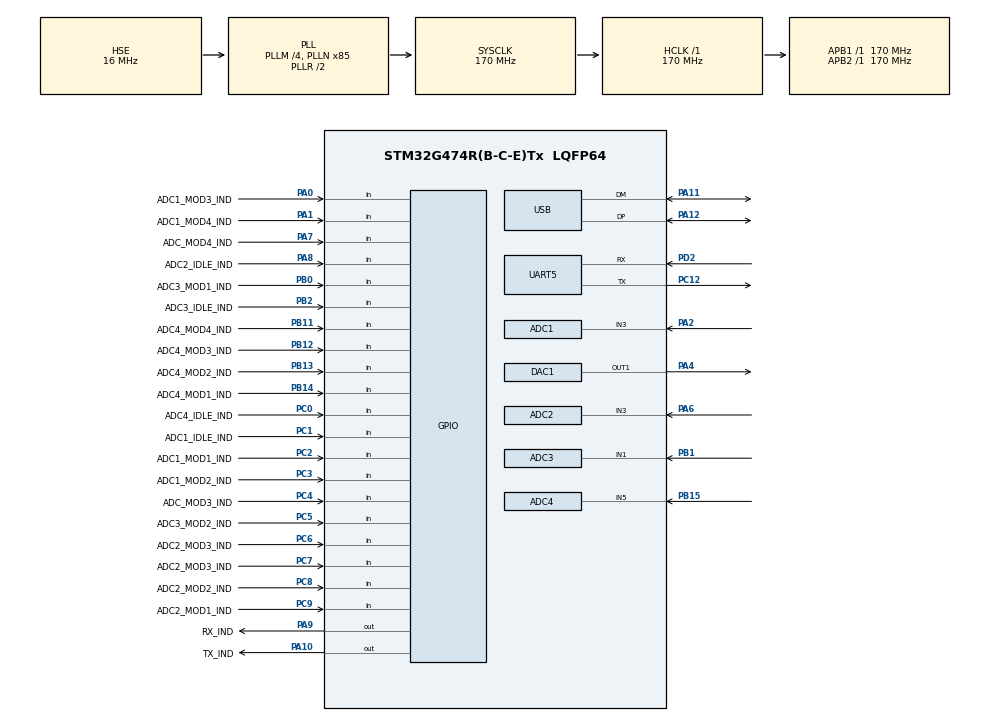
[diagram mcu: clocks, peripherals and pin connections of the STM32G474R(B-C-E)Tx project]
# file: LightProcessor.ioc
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ADC1.Channel-1\#ChannelRegularConversion=ADC_CHANNEL_3
ADC1.NbrOfConversionFlag=1
ADC1.OffsetNumber-1\#ChannelRegularConversion=ADC_OFFSET_NONE
ADC1.Rank-1\#ChannelRegularConversion=1
ADC1.SamplingTime-1\#ChannelRegularConversion=ADC_SAMPLETIME_2CYCLES_5
ADC1.ScanConvMode-ADC_Settings=ADC_SCAN_DISABLE
ADC1.master=1
ADC2.Channel-0\#ChannelRegularConversion=ADC_CHANNEL_3
ADC2.NbrOfConversionFlag=1
ADC2.OffsetNumber-0\#ChannelRegularConversion=ADC_OFFSET_NONE
ADC2.Rank-0\#ChannelRegularConversion=1
ADC2.SamplingTime-0\#ChannelRegularConversion=ADC_SAMPLETIME_2CYCLES_5
ADC3.Channel-0\#ChannelRegularConversion=ADC_CHANNEL_1
ADC3.NbrOfConversionFlag=1
ADC3.OffsetNumber-0\#ChannelRegularConversion=ADC_OFFSET_NONE
ADC3.Rank-0\#ChannelRegularConversion=1
ADC3.SamplingTime-0\#ChannelRegularConversion=ADC_SAMPLETIME_2CYCLES_5
ADC3.master=1
ADC4.Channel-0\#ChannelRegularConversion=ADC_CHANNEL_5
ADC4.NbrOfConversionFlag=1
ADC4.OffsetNumber-0\#ChannelRegularConversion=ADC_OFFSET_NONE
ADC4.Rank-0\#ChannelRegularConversion=1
ADC4.SamplingTime-0\#ChannelRegularConversion=ADC_SAMPLETIME_2CYCLES_5
Mcu.Family=STM32G4
Mcu.Name=STM32G474R(B-C-E)Tx
Mcu.Package=LQFP64
NVIC.ADC1_2_IRQn=true\:0\:0\:false\:false\:true\:true\:true\:true
NVIC.ADC3_IRQn=true\:0\:0\:false\:false\:true\:true\:true\:true
NVIC.ADC4_IRQn=true\:0\:0\:false\:false\:true\:true\:true\:true
NVIC.PriorityGroup=NVIC_PRIORITYGROUP_4
NVIC.TIM2_IRQn=true\:0\:0\:false\:false\:true\:true\:true\:true
NVIC.UART5_IRQn=true\:0\:0\:false\:false\:true\:true\:true\:true
PA0.GPIO_Label=ADC1_MOD3_IND
PA0.GPIO_PuPd=GPIO_PULLDOWN
PA0.Signal=GPIO_Input
PA1.GPIO_Label=ADC1_MOD4_IND
PA1.GPIO_PuPd=GPIO_PULLDOWN
PA1.Signal=GPIO_Input
PA10.GPIO_Label=TX_IND
PA10.GPIO_PuPd=GPIO_PULLDOWN
PA10.Signal=GPIO_Output
PA11.Mode=Device
PA11.Signal=USB_DM
PA12.Mode=Device
PA12.Signal=USB_DP
PA13.Mode=Serial_Wire
PA13.Signal=SYS_JTMS-SWDIO
PA14.Mode=Serial_Wire
PA14.Signal=SYS_JTCK-SWCLK
PA2.Mode=IN3-Single-Ended
PA2.Signal=ADC1_IN3
PA4.Signal=COMP_DAC11_group
PA6.Mode=IN3-Single-Ended
PA6.Signal=ADC2_IN3
PA7.GPIO_Label=ADC_MOD4_IND
PA7.GPIO_PuPd=GPIO_PULLDOWN
PA7.Signal=GPIO_Input
PA8.GPIO_Label=ADC2_IDLE_IND
PA8.GPIO_PuPd=GPIO_PULLDOWN
PA8.Signal=GPIO_Input
PA9.GPIO_Label=RX_IND
PA9.GPIO_PuPd=GPIO_PULLDOWN
PA9.Signal=GPIO_Output
PB0.GPIO_Label=ADC3_MOD1_IND
PB0.GPIO_PuPd=GPIO_PULLDOWN
PB0.Signal=GPIO_Input
PB1.Mode=IN1-Single-Ended
PB1.Signal=ADC3_IN1
PB11.GPIO_Label=ADC4_MOD4_IND
PB11.GPIO_PuPd=GPIO_PULLDOWN
PB11.Signal=GPIO_Input
PB12.GPIO_Label=ADC4_MOD3_IND
PB12.GPIO_PuPd=GPIO_PULLDOWN
PB12.Signal=GPIO_Input
PB13.GPIO_Label=ADC4_MOD2_IND
PB13.GPIO_PuPd=GPIO_PULLDOWN
PB13.Signal=GPIO_Input
PB14.GPIO_Label=ADC4_MOD1_IND
PB14.GPIO_PuPd=GPIO_PULLDOWN
PB14.Signal=GPIO_Input
PB15.Mode=IN5-Single-Ended
PB15.Signal=ADC4_IN5
PB2.GPIO_Label=ADC3_IDLE_IND
PB2.GPIO_PuPd=GPIO_PULLDOWN
PB2.Signal=GPIO_Input
PC0.GPIO_Label=ADC4_IDLE_IND
PC0.GPIO_PuPd=GPIO_PULLDOWN
PC0.Signal=GPIO_Input
PC1.GPIO_Label=ADC1_IDLE_IND
PC1.GPIO_PuPd=GPIO_PULLDOWN
PC1.Signal=GPIO_Input
PC12.Mode=Asynchronous
PC12.Signal=UART5_TX
PC2.GPIO_Label=ADC1_MOD1_IND
PC2.GPIO_PuPd=GPIO_PULLDOWN
PC2.Signal=GPIO_Input
PC3.GPIO_Label=ADC1_MOD2_IND
PC3.GPIO_PuPd=GPIO_PULLDOWN
PC3.Signal=GPIO_Input
PC4.GPIO_Label=ADC_MOD3_IND
PC4.GPIO_PuPd=GPIO_PULLDOWN
PC4.Signal=GPIO_Input
PC5.GPIO_Label=ADC3_MOD2_IND
PC5.GPIO_PuPd=GPIO_PULLDOWN
PC5.Signal=GPIO_Input
PC6.GPIO_Label=ADC2_MOD3_IND
PC6.GPIO_PuPd=GPIO_PULLDOWN
PC6.Signal=GPIO_Input
PC7.GPIO_Label=ADC2_MOD3_IND
PC7.GPIO_PuPd=GPIO_PULLDOWN
PC7.Signal=GPIO_Input
PC8.GPIO_Label=ADC2_MOD2_IND
PC8.GPIO_PuPd=GPIO_PULLDOWN
PC8.Signal=GPIO_Input
PC9.GPIO_Label=ADC2_MOD1_IND
PC9.GPIO_PuPd=GPIO_PULLDOWN
PC9.Signal=GPIO_Input
PD2.Mode=Asynchronous
PD2.Signal=UART5_RX
PF0-OSC_IN.Mode=HSE-External-Oscillator
PF0-OSC_IN.Signal=RCC_OSC_IN
PF1-OSC_OUT.Mode=HSE-External-Oscillator
PF1-OSC_OUT.Signal=RCC_OSC_OUT
ProjectManager.HeapSize=0x200
ProjectManager.StackSize=0x400
ProjectManager.TargetToolchain=STM32CubeIDE
RCC.ADC12Freq_Value=170000000
RCC.ADC345Freq_Value=170000000
RCC.AHBFreq_Value=170000000
RCC.APB1Freq_Value=170000000
RCC.APB1TimFreq_Value=170000000
RCC.APB2Freq_Value=170000000
RCC.APB2TimFreq_Value=170000000
RCC.CK48CLockSelection=RCC_USBCLKSOURCE_HSI48
RCC.CortexFreq_Value=170000000
RCC.EXTERNAL_CLOCK_VALUE=12288000
RCC.HCLKFreq_Value=170000000
RCC.HSE_VALUE=16000000
RCC.HSI48_VALUE=48000000
RCC.HSI_VALUE=16000000
RCC.LSE_VALUE=32768
RCC.PLLM=RCC_PLLM_DIV4
RCC.PLLN=85
RCC.PLLSourceVirtual=RCC_PLLSOURCE_HSE
RCC.SYSCLKFreq_VALUE=170000000
RCC.SYSCLKSource=RCC_SYSCLKSOURCE_PLLCLK
RCC.USBFreq_Value=48000000
RCC.VCOOutputFreq_Value=340000000
SH.COMP_DAC11_group.0=DAC1_OUT1,DAC_OUT1
TIM2.AutoReloadPreload=TIM_AUTORELOAD_PRELOAD_DISABLE
TIM2.PeriodNoDither=84
TIM2.Prescaler=5
UART5.FIFOMode=FIFOMODE_ENABLE
VP_SYS_VS_DBSignals.Mode=DisableDeadBatterySignals
VP_TIM2_VS_ClockSourceINT.Mode=Internal
board=custom

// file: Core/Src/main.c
/* USER CODE BEGIN Header */
/**
  ******************************************************************************
  * @file           : main.c
  * @brief          : Main program body
  ******************************************************************************
  * @attention
  *
  * Copyright (c) 2025 STMicroelectronics.
  * All rights reserved.
  *
  * This software is licensed under terms that can be found in the LICENSE file
  * in the root directory of this software component.
  * If no LICENSE file comes with this software, it is provided AS-IS.
  *
  ******************************************************************************
  */
/* USER CODE END Header */
#include "main.h"

ADC_HandleTypeDef hadc1;
ADC_HandleTypeDef hadc2;
ADC_HandleTypeDef hadc3;
ADC_HandleTypeDef hadc4;

DAC_HandleTypeDef hdac1;

TIM_HandleTypeDef htim2;

UART_HandleTypeDef huart5;

PCD_HandleTypeDef hpcd_USB_FS;

void SystemClock_Config(void);
static void MX_GPIO_Init(void);
static void MX_UART5_Init(void);
static void MX_ADC1_Init(void);
static void MX_ADC2_Init(void);
static void MX_ADC3_Init(void);
static void MX_ADC4_Init(void);
static void MX_TIM2_Init(void);
static void MX_DAC1_Init(void);
static void MX_USB_PCD_Init(void);

int main(void)
{

  /* USER CODE BEGIN 1 */
	SCB->VTOR = FLASH_BASE;
  /* USER CODE END 1 */

  /* MCU Configuration--------------------------------------------------------*/

  /* Reset of all peripherals, Initializes the Flash interface and the Systick. */
  HAL_Init();

  /* Configure the system clock */
  SystemClock_Config();

  /* Initialize all configured peripherals */
  MX_GPIO_Init();
  MX_UART5_Init();
  MX_ADC1_Init();
  MX_ADC2_Init();
  MX_ADC3_Init();
  MX_ADC4_Init();
  MX_TIM2_Init();
  MX_DAC1_Init();
  MX_USB_PCD_Init();
  /* USER CODE BEGIN 2 */
  run();
  /* USER CODE END 2 */

  /* Infinite loop */
  while (1)
  {

  }
}

void SystemClock_Config(void)
{
  RCC_OscInitTypeDef RCC_OscInitStruct = {0};
  RCC_ClkInitTypeDef RCC_ClkInitStruct = {0};

  /** Configure the main internal regulator output voltage
  */
  HAL_PWREx_ControlVoltageScaling(PWR_REGULATOR_VOLTAGE_SCALE1_BOOST);

  /** Initializes the RCC Oscillators according to the specified parameters
  * in the RCC_OscInitTypeDef structure.
  */
  RCC_OscInitStruct.OscillatorType = RCC_OSCILLATORTYPE_HSI48|RCC_OSCILLATORTYPE_HSE;
  RCC_OscInitStruct.HSEState = RCC_HSE_ON;
  RCC_OscInitStruct.HSI48State = RCC_HSI48_ON;
  RCC_OscInitStruct.PLL.PLLState = RCC_PLL_ON;
  RCC_OscInitStruct.PLL.PLLSource = RCC_PLLSOURCE_HSE;
  RCC_OscInitStruct.PLL.PLLM = RCC_PLLM_DIV4;
  RCC_OscInitStruct.PLL.PLLN = 85;
  RCC_OscInitStruct.PLL.PLLP = RCC_PLLP_DIV2;
  RCC_OscInitStruct.PLL.PLLQ = RCC_PLLQ_DIV2;
  RCC_OscInitStruct.PLL.PLLR = RCC_PLLR_DIV2;
  if (HAL_RCC_OscConfig(&RCC_OscInitStruct) != HAL_OK)
  {
    Error_Handler();
  }

  /** Initializes the CPU, AHB and APB buses clocks
  */
  RCC_ClkInitStruct.ClockType = RCC_CLOCKTYPE_HCLK|RCC_CLOCKTYPE_SYSCLK
                              |RCC_CLOCKTYPE_PCLK1|RCC_CLOCKTYPE_PCLK2;
  RCC_ClkInitStruct.SYSCLKSource = RCC_SYSCLKSOURCE_PLLCLK;
  RCC_ClkInitStruct.AHBCLKDivider = RCC_SYSCLK_DIV1;
  RCC_ClkInitStruct.APB1CLKDivider = RCC_HCLK_DIV1;
  RCC_ClkInitStruct.APB2CLKDivider = RCC_HCLK_DIV1;

  if (HAL_RCC_ClockConfig(&RCC_ClkInitStruct, FLASH_LATENCY_4) != HAL_OK)
  {
    Error_Handler();
  }
}

static void MX_ADC1_Init(void)
{

  ADC_MultiModeTypeDef multimode = {0};
  ADC_ChannelConfTypeDef sConfig = {0};

  /** Common config
  */
  hadc1.Instance = ADC1;
  hadc1.Init.ClockPrescaler = ADC_CLOCK_SYNC_PCLK_DIV4;
  hadc1.Init.Resolution = ADC_RESOLUTION_12B;
  hadc1.Init.DataAlign = ADC_DATAALIGN_RIGHT;
  hadc1.Init.GainCompensation = 0;
  hadc1.Init.ScanConvMode = ADC_SCAN_DISABLE;
  hadc1.Init.EOCSelection = ADC_EOC_SINGLE_CONV;
  hadc1.Init.LowPowerAutoWait = DISABLE;
  hadc1.Init.ContinuousConvMode = DISABLE;
  hadc1.Init.NbrOfConversion = 1;
  hadc1.Init.DiscontinuousConvMode = DISABLE;
  hadc1.Init.ExternalTrigConv = ADC_SOFTWARE_START;
  hadc1.Init.ExternalTrigConvEdge = ADC_EXTERNALTRIGCONVEDGE_NONE;
  hadc1.Init.DMAContinuousRequests = DISABLE;
  hadc1.Init.Overrun = ADC_OVR_DATA_PRESERVED;
  hadc1.Init.OversamplingMode = DISABLE;
  if (HAL_ADC_Init(&hadc1) != HAL_OK)
  {
    Error_Handler();
  }

  /** Configure the ADC multi-mode
  */
  multimode.Mode = ADC_MODE_INDEPENDENT;
  if (HAL_ADCEx_MultiModeConfigChannel(&hadc1, &multimode) != HAL_OK)
  {
    Error_Handler();
  }

  /** Configure Regular Channel
  */
  sConfig.Channel = ADC_CHANNEL_3;
  sConfig.Rank = ADC_REGULAR_RANK_1;
  sConfig.SamplingTime = ADC_SAMPLETIME_2CYCLES_5;
  sConfig.SingleDiff = ADC_SINGLE_ENDED;
  sConfig.OffsetNumber = ADC_OFFSET_NONE;
  sConfig.Offset = 0;
  if (HAL_ADC_ConfigChannel(&hadc1, &sConfig) != HAL_OK)
  {
    Error_Handler();
  }

}

static void MX_ADC2_Init(void)
{

  ADC_ChannelConfTypeDef sConfig = {0};

  /** Common config
  */
  hadc2.Instance = ADC2;
  hadc2.Init.ClockPrescaler = ADC_CLOCK_SYNC_PCLK_DIV4;
  hadc2.Init.Resolution = ADC_RESOLUTION_12B;
  hadc2.Init.DataAlign = ADC_DATAALIGN_RIGHT;
  hadc2.Init.GainCompensation = 0;
  hadc2.Init.ScanConvMode = ADC_SCAN_DISABLE;
  hadc2.Init.EOCSelection = ADC_EOC_SINGLE_CONV;
  hadc2.Init.LowPowerAutoWait = DISABLE;
  hadc2.Init.ContinuousConvMode = DISABLE;
  hadc2.Init.NbrOfConversion = 1;
  hadc2.Init.DiscontinuousConvMode = DISABLE;
  hadc2.Init.ExternalTrigConv = ADC_SOFTWARE_START;
  hadc2.Init.ExternalTrigConvEdge = ADC_EXTERNALTRIGCONVEDGE_NONE;
  hadc2.Init.DMAContinuousRequests = DISABLE;
  hadc2.Init.Overrun = ADC_OVR_DATA_PRESERVED;
  hadc2.Init.OversamplingMode = DISABLE;
  if (HAL_ADC_Init(&hadc2) != HAL_OK)
  {
    Error_Handler();
  }

  /** Configure Regular Channel
  */
  sConfig.Channel = ADC_CHANNEL_3;
  sConfig.Rank = ADC_REGULAR_RANK_1;
  sConfig.SamplingTime = ADC_SAMPLETIME_2CYCLES_5;
  sConfig.SingleDiff = ADC_SINGLE_ENDED;
  sConfig.OffsetNumber = ADC_OFFSET_NONE;
  sConfig.Offset = 0;
  if (HAL_ADC_ConfigChannel(&hadc2, &sConfig) != HAL_OK)
  {
    Error_Handler();
  }

}

static void MX_ADC3_Init(void)
{

  ADC_MultiModeTypeDef multimode = {0};
  ADC_ChannelConfTypeDef sConfig = {0};

  /** Common config
  */
  hadc3.Instance = ADC3;
  hadc3.Init.ClockPrescaler = ADC_CLOCK_SYNC_PCLK_DIV4;
  hadc3.Init.Resolution = ADC_RESOLUTION_12B;
  hadc3.Init.DataAlign = ADC_DATAALIGN_RIGHT;
  hadc3.Init.GainCompensation = 0;
  hadc3.Init.ScanConvMode = ADC_SCAN_DISABLE;
  hadc3.Init.EOCSelection = ADC_EOC_SINGLE_CONV;
  hadc3.Init.LowPowerAutoWait = DISABLE;
  hadc3.Init.ContinuousConvMode = DISABLE;
  hadc3.Init.NbrOfConversion = 1;
  hadc3.Init.DiscontinuousConvMode = DISABLE;
  hadc3.Init.ExternalTrigConv = ADC_SOFTWARE_START;
  hadc3.Init.ExternalTrigConvEdge = ADC_EXTERNALTRIGCONVEDGE_NONE;
  hadc3.Init.DMAContinuousRequests = DISABLE;
  hadc3.Init.Overrun = ADC_OVR_DATA_PRESERVED;
  hadc3.Init.OversamplingMode = DISABLE;
  if (HAL_ADC_Init(&hadc3) != HAL_OK)
  {
    Error_Handler();
  }

  /** Configure the ADC multi-mode
  */
  multimode.Mode = ADC_MODE_INDEPENDENT;
  if (HAL_ADCEx_MultiModeConfigChannel(&hadc3, &multimode) != HAL_OK)
  {
    Error_Handler();
  }

  /** Configure Regular Channel
  */
  sConfig.Channel = ADC_CHANNEL_1;
  sConfig.Rank = ADC_REGULAR_RANK_1;
  sConfig.SamplingTime = ADC_SAMPLETIME_2CYCLES_5;
  sConfig.SingleDiff = ADC_SINGLE_ENDED;
  sConfig.OffsetNumber = ADC_OFFSET_NONE;
  sConfig.Offset = 0;
  if (HAL_ADC_ConfigChannel(&hadc3, &sConfig) != HAL_OK)
  {
    Error_Handler();
  }

}

static void MX_ADC4_Init(void)
{

  ADC_ChannelConfTypeDef sConfig = {0};

  /** Common config
  */
  hadc4.Instance = ADC4;
  hadc4.Init.ClockPrescaler = ADC_CLOCK_SYNC_PCLK_DIV4;
  hadc4.Init.Resolution = ADC_RESOLUTION_12B;
  hadc4.Init.DataAlign = ADC_DATAALIGN_RIGHT;
  hadc4.Init.GainCompensation = 0;
  hadc4.Init.ScanConvMode = ADC_SCAN_DISABLE;
  hadc4.Init.EOCSelection = ADC_EOC_SINGLE_CONV;
  hadc4.Init.LowPowerAutoWait = DISABLE;
  hadc4.Init.ContinuousConvMode = DISABLE;
  hadc4.Init.NbrOfConversion = 1;
  hadc4.Init.DiscontinuousConvMode = DISABLE;
  hadc4.Init.ExternalTrigConv = ADC_SOFTWARE_START;
  hadc4.Init.ExternalTrigConvEdge = ADC_EXTERNALTRIGCONVEDGE_NONE;
  hadc4.Init.DMAContinuousRequests = DISABLE;
  hadc4.Init.Overrun = ADC_OVR_DATA_PRESERVED;
  hadc4.Init.OversamplingMode = DISABLE;
  if (HAL_ADC_Init(&hadc4) != HAL_OK)
  {
    Error_Handler();
  }

  /** Configure Regular Channel
  */
  sConfig.Channel = ADC_CHANNEL_5;
  sConfig.Rank = ADC_REGULAR_RANK_1;
  sConfig.SamplingTime = ADC_SAMPLETIME_2CYCLES_5;
  sConfig.SingleDiff = ADC_SINGLE_ENDED;
  sConfig.OffsetNumber = ADC_OFFSET_NONE;
  sConfig.Offset = 0;
  if (HAL_ADC_ConfigChannel(&hadc4, &sConfig) != HAL_OK)
  {
    Error_Handler();
  }

}

static void MX_DAC1_Init(void)
{

  DAC_ChannelConfTypeDef sConfig = {0};

  /** DAC Initialization
  */
  hdac1.Instance = DAC1;
  if (HAL_DAC_Init(&hdac1) != HAL_OK)
  {
    Error_Handler();
  }

  /** DAC channel OUT1 config
  */
  sConfig.DAC_HighFrequency = DAC_HIGH_FREQUENCY_INTERFACE_MODE_AUTOMATIC;
  sConfig.DAC_DMADoubleDataMode = DISABLE;
  sConfig.DAC_SignedFormat = DISABLE;
  sConfig.DAC_SampleAndHold = DAC_SAMPLEANDHOLD_DISABLE;
  sConfig.DAC_Trigger = DAC_TRIGGER_NONE;
  sConfig.DAC_Trigger2 = DAC_TRIGGER_NONE;
  sConfig.DAC_OutputBuffer = DAC_OUTPUTBUFFER_ENABLE;
  sConfig.DAC_ConnectOnChipPeripheral = DAC_CHIPCONNECT_EXTERNAL;
  sConfig.DAC_UserTrimming = DAC_TRIMMING_FACTORY;
  if (HAL_DAC_ConfigChannel(&hdac1, &sConfig, DAC_CHANNEL_1) != HAL_OK)
  {
    Error_Handler();
  }

}

static void MX_TIM2_Init(void)
{

  TIM_ClockConfigTypeDef sClockSourceConfig = {0};
  TIM_MasterConfigTypeDef sMasterConfig = {0};

  /* USER CODE BEGIN TIM2_Init 1 */
  __HAL_RCC_TIM2_CLK_ENABLE();
  /* USER CODE END TIM2_Init 1 */
  htim2.Instance = TIM2;
  htim2.Init.Prescaler = 5;
  htim2.Init.CounterMode = TIM_COUNTERMODE_UP;
  htim2.Init.Period = 84;
  htim2.Init.ClockDivision = TIM_CLOCKDIVISION_DIV1;
  htim2.Init.AutoReloadPreload = TIM_AUTORELOAD_PRELOAD_DISABLE;
  if (HAL_TIM_Base_Init(&htim2) != HAL_OK)
  {
    Error_Handler();
  }
  sClockSourceConfig.ClockSource = TIM_CLOCKSOURCE_INTERNAL;
  if (HAL_TIM_ConfigClockSource(&htim2, &sClockSourceConfig) != HAL_OK)
  {
    Error_Handler();
  }
  sMasterConfig.MasterOutputTrigger = TIM_TRGO_RESET;
  sMasterConfig.MasterSlaveMode = TIM_MASTERSLAVEMODE_DISABLE;
  if (HAL_TIMEx_MasterConfigSynchronization(&htim2, &sMasterConfig) != HAL_OK)
  {
    Error_Handler();
  }
  /* USER CODE BEGIN TIM2_Init 2 */
  HAL_NVIC_SetPriority(TIM2_IRQn, 0, 0);
  HAL_NVIC_EnableIRQ(TIM2_IRQn);
  /* USER CODE END TIM2_Init 2 */

}

static void MX_UART5_Init(void)
{

  huart5.Instance = UART5;
  huart5.Init.BaudRate = 115200;
  huart5.Init.WordLength = UART_WORDLENGTH_8B;
  huart5.Init.StopBits = UART_STOPBITS_1;
  huart5.Init.Parity = UART_PARITY_NONE;
  huart5.Init.Mode = UART_MODE_TX_RX;
  huart5.Init.HwFlowCtl = UART_HWCONTROL_NONE;
  huart5.Init.OverSampling = UART_OVERSAMPLING_16;
  huart5.Init.OneBitSampling = UART_ONE_BIT_SAMPLE_DISABLE;
  huart5.Init.ClockPrescaler = UART_PRESCALER_DIV1;
  huart5.AdvancedInit.AdvFeatureInit = UART_ADVFEATURE_NO_INIT;
  if (HAL_UART_Init(&huart5) != HAL_OK)
  {
    Error_Handler();
  }
  if (HAL_UARTEx_SetTxFifoThreshold(&huart5, UART_TXFIFO_THRESHOLD_1_8) != HAL_OK)
  {
    Error_Handler();
  }
  if (HAL_UARTEx_SetRxFifoThreshold(&huart5, UART_RXFIFO_THRESHOLD_1_8) != HAL_OK)
  {
    Error_Handler();
  }
  if (HAL_UARTEx_EnableFifoMode(&huart5) != HAL_OK)
  {
    Error_Handler();
  }

}

static void MX_USB_PCD_Init(void)
{

  hpcd_USB_FS.Instance = USB;
  hpcd_USB_FS.Init.dev_endpoints = 8;
  hpcd_USB_FS.Init.speed = PCD_SPEED_FULL;
  hpcd_USB_FS.Init.phy_itface = PCD_PHY_EMBEDDED;
  hpcd_USB_FS.Init.Sof_enable = DISABLE;
  hpcd_USB_FS.Init.low_power_enable = DISABLE;
  hpcd_USB_FS.Init.lpm_enable = DISABLE;
  hpcd_USB_FS.Init.battery_charging_enable = DISABLE;
  if (HAL_PCD_Init(&hpcd_USB_FS) != HAL_OK)
  {
    Error_Handler();
  }

}

static void MX_GPIO_Init(void)
{
  GPIO_InitTypeDef GPIO_InitStruct = {0};

  /* GPIO Ports Clock Enable */
  __HAL_RCC_GPIOF_CLK_ENABLE();
  __HAL_RCC_GPIOC_CLK_ENABLE();
  __HAL_RCC_GPIOA_CLK_ENABLE();
  __HAL_RCC_GPIOB_CLK_ENABLE();
  __HAL_RCC_GPIOD_CLK_ENABLE();

  /*Configure GPIO pin Output Level */
  HAL_GPIO_WritePin(GPIOA, RX_IND_Pin|TX_IND_Pin, GPIO_PIN_RESET);

  /*Configure GPIO pins : ADC4_IDLE_IND_Pin ADC1_IDLE_IND_Pin ADC1_MOD1_IND_Pin ADC1_MOD2_IND_Pin
                           ADC_MOD3_IND_Pin ADC3_MOD2_IND_Pin ADC2_MOD3_IND_Pin ADC2_MOD3_INDC7_Pin
                           ADC2_MOD2_IND_Pin ADC2_MOD1_IND_Pin */
  GPIO_InitStruct.Pin = ADC4_IDLE_IND_Pin|ADC1_IDLE_IND_Pin|ADC1_MOD1_IND_Pin|ADC1_MOD2_IND_Pin
                          |ADC_MOD3_IND_Pin|ADC3_MOD2_IND_Pin|ADC2_MOD3_IND_Pin|ADC2_MOD3_INDC7_Pin
                          |ADC2_MOD2_IND_Pin|ADC2_MOD1_IND_Pin;
  GPIO_InitStruct.Mode = GPIO_MODE_INPUT;
  GPIO_InitStruct.Pull = GPIO_PULLDOWN;
  HAL_GPIO_Init(GPIOC, &GPIO_InitStruct);

  /*Configure GPIO pins : ADC1_MOD3_IND_Pin ADC1_MOD4_IND_Pin ADC_MOD4_IND_Pin ADC2_IDLE_IND_Pin */
  GPIO_InitStruct.Pin = ADC1_MOD3_IND_Pin|ADC1_MOD4_IND_Pin|ADC_MOD4_IND_Pin|ADC2_IDLE_IND_Pin;
  GPIO_InitStruct.Mode = GPIO_MODE_INPUT;
  GPIO_InitStruct.Pull = GPIO_PULLDOWN;
  HAL_GPIO_Init(GPIOA, &GPIO_InitStruct);

  /*Configure GPIO pins : ADC3_MOD1_IND_Pin ADC3_IDLE_IND_Pin ADC4_MOD4_IND_Pin ADC4_MOD3_IND_Pin
                           ADC4_MOD2_IND_Pin ADC4_MOD1_IND_Pin */
  GPIO_InitStruct.Pin = ADC3_MOD1_IND_Pin|ADC3_IDLE_IND_Pin|ADC4_MOD4_IND_Pin|ADC4_MOD3_IND_Pin
                          |ADC4_MOD2_IND_Pin|ADC4_MOD1_IND_Pin;
  GPIO_InitStruct.Mode = GPIO_MODE_INPUT;
  GPIO_InitStruct.Pull = GPIO_PULLDOWN;
  HAL_GPIO_Init(GPIOB, &GPIO_InitStruct);

  /*Configure GPIO pins : RX_IND_Pin TX_IND_Pin */
  GPIO_InitStruct.Pin = RX_IND_Pin|TX_IND_Pin;
  GPIO_InitStruct.Mode = GPIO_MODE_OUTPUT_PP;
  GPIO_InitStruct.Pull = GPIO_PULLDOWN;
  GPIO_InitStruct.Speed = GPIO_SPEED_FREQ_LOW;
  HAL_GPIO_Init(GPIOA, &GPIO_InitStruct);

}

void Error_Handler(void)
{
  __disable_irq();
  while (1)
  {
  }
}
